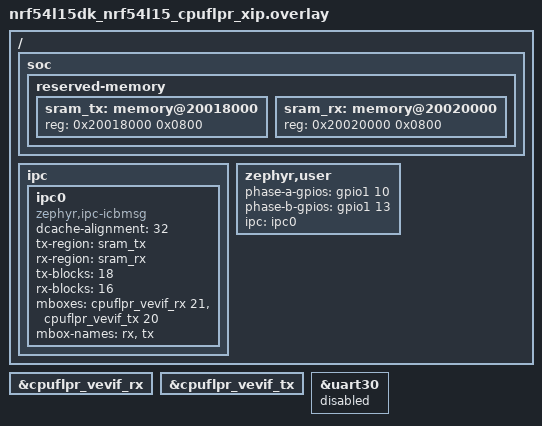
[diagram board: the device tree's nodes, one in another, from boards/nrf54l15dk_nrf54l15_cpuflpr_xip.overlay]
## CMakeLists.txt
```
# Copyright (c) 2025 Nordic Semiconductor ASA
# SPDX-License-Identifier: Apache-2.0

cmake_minimum_required(VERSION 3.20.0)

find_package(Zephyr REQUIRED HINTS $ENV{ZEPHYR_BASE})
project(soft_qdec)

target_sources(app PRIVATE src/main.c)
```

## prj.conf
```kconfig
# Copyright (c) 2025 Nordic Semiconductor ASA
# SPDX-License-Identifier: Apache-2.0

CONFIG_GPIO=y
CONFIG_IPC_SERVICE=y
CONFIG_MBOX=y

CONFIG_SERIAL=n
CONFIG_CONSOLE=n
CONFIG_UART_CONSOLE=n
```

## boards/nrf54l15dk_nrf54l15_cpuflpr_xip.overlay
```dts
/ {
	soc {
		reserved-memory {
			#address-cells = <1>;
			#size-cells = <1>;

			sram_tx: memory@20018000 {
				reg = <0x20018000 0x0800>;
			};

			sram_rx: memory@20020000 {
				reg = <0x20020000 0x0800>;
			};
		};
	};

	ipc {
		ipc0: ipc0 {
			compatible = "zephyr,ipc-icbmsg";
			dcache-alignment = <32>;
			tx-region = <&sram_tx>;
			rx-region = <&sram_rx>;
			tx-blocks = <18>;
			rx-blocks = <16>;
			mboxes = <&cpuflpr_vevif_rx 21>, <&cpuflpr_vevif_tx 20>;
			mbox-names = "rx", "tx";
			status = "okay";
		};
	};

	zephyr,user {
		phase-a-gpios = <&gpio1 10 GPIO_ACTIVE_HIGH>;
		phase-b-gpios = <&gpio1 13 GPIO_ACTIVE_HIGH>;
		ipc = <&ipc0>;
	};
};

&cpuflpr_vevif_rx {
	status = "okay";
};

&cpuflpr_vevif_tx {
	status = "okay";
};

&uart30 {
	status = "disabled";
};
```

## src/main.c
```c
/*
 * Copyright (c) 2025 Nordic Semiconductor ASA
 *
 * SPDX-License-Identifier: Apache-2.0
 */

#include <zephyr/drivers/gpio.h>
#include <zephyr/ipc/ipc_service.h>
#include <zephyr/sys/byteorder.h>
#include <zephyr/sys/atomic.h>

static const struct gpio_dt_spec phase_a = GPIO_DT_SPEC_GET(DT_PATH(zephyr_user), phase_a_gpios);
static const struct gpio_dt_spec phase_b = GPIO_DT_SPEC_GET(DT_PATH(zephyr_user), phase_b_gpios);
static const struct device *ipc_dev = DEVICE_DT_GET(DT_PROP(DT_PATH(zephyr_user), ipc));
static uint32_t phases_last;
static uint32_t phases_current;
static atomic_t accumulated;
static struct ipc_ept ep;

static void get_current_phases(void)
{
	phases_current = (gpio_pin_get_dt(&phase_a) << 1) | gpio_pin_get_dt(&phase_b);
}

static void update_last_phases(void)
{
	phases_last = phases_current;
}

static bool phases_changed(void)
{
	return phases_current != phases_last;
}

static void accumulate_step(void)
{
	switch (phases_last) {
	case 0:
		if (phases_current == 1) {
			atomic_inc(&accumulated);
		} else if (phases_current == 2) {
			atomic_dec(&accumulated);
		}

		break;

	case 1:
		if (phases_current == 3) {
			atomic_inc(&accumulated);
		} else if (phases_current == 0) {
			atomic_dec(&accumulated);
		}

		break;

	case 2:
		if (phases_current == 0) {
			atomic_inc(&accumulated);
		} else if (phases_current == 3) {
			atomic_dec(&accumulated);
		}

		break;

	case 3:
		if (phases_current == 2) {
			atomic_inc(&accumulated);
		} else if (phases_current == 1) {
			atomic_dec(&accumulated);
		}

		break;

	default:
		break;
	}
}

static void ep_recv(const void *data, size_t len, void *priv)
{
	uint8_t ser[sizeof(int32_t)];

	sys_put_le32(accumulated, ser);
	atomic_set(&accumulated, 0);
	ipc_service_send(&ep, ser, sizeof(ser));
}

static const struct ipc_ept_cfg ep_cfg = {
	.cb = {
		.received = ep_recv,
	},
};

int main(void)
{
	int ret;

	gpio_pin_configure_dt(&phase_a, GPIO_INPUT);
	gpio_pin_configure_dt(&phase_b, GPIO_INPUT);

	get_current_phases();
	update_last_phases();

	ret = ipc_service_open_instance(ipc_dev);
	if (ret < 0) {
		return ret;
	}

	ret = ipc_service_register_endpoint(ipc_dev, &ep, &ep_cfg);
	if (ret < 0) {
		return ret;
	}

	while (1) {
		get_current_phases();

		if (!phases_changed()) {
			continue;
		}

		accumulate_step();
		update_last_phases();
	}

	return 0;
}
```
